# Polarfire SoC register map
Vendor: Microchip; File version: 1.0
CPU: Microchip PolarFire SoC 1.0, little endian
Registers are 32-bit, read-write, reset 0x0 unless marked. A register's access mark holds for its fields unless they carry their own. Offsets are from the block's base; [hi:lo] are bit positions; {n}, {i} and the like mark numbered series; 'fields as' and 'values as' point back to an identical list.

## CAN_A_LO — CAN_A_LO Controller
Base 0x2010C000
Same registers: CAN_B_LO 0x2010D000, CAN_A_HI 0x2810C000, CAN_B_HI 0x2810D000
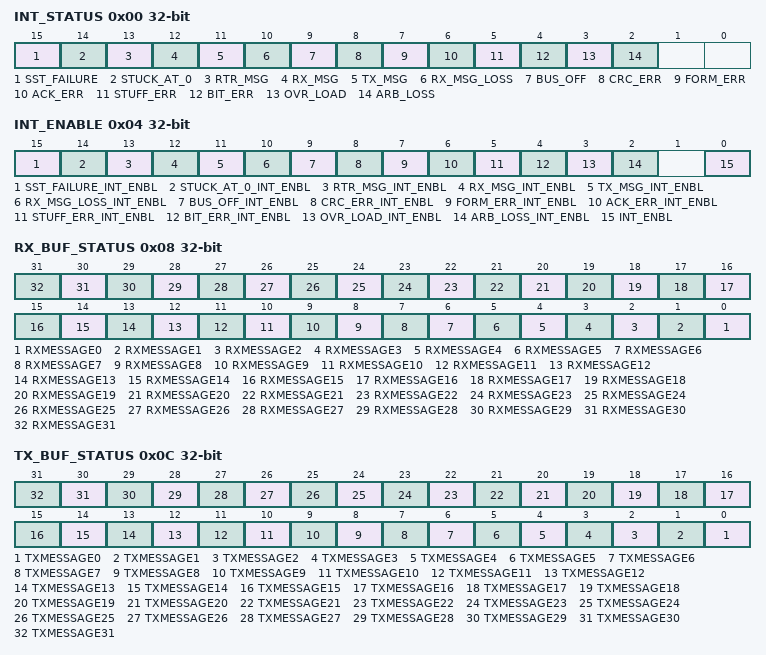
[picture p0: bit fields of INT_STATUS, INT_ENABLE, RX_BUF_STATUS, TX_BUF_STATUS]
0x00 INT_STATUS — Interrupt status register
  [15] SST_FAILURE — Single-shot transmission failure 0: Normal operation 1: A buffer set for single shot transmission experienced an arbitration loss or a bus error during transmission.
  [14] STUCK_AT_0 — Stuck at dominant error 0: Normal operation 1: Indicates if receive (RX) input remains stuck at 0 (dominant level) for more than 11 consecutive bit times.
  [13] RTR_MSG — RTR auto-reply message sent 0: Normal operation 1: Indicates that a RTR auto-reply message was sent.
  [12] RX_MSG — Receive message available 0: Normal operation 1: Indicates a new message was successfully received and stored in a receive buffer which has its RxIntEbl flag asserted.
  [11] TX_MSG — Message transmitted 0: Normal operation 1: Indicates a message was successfully sent from a transmit buffer which has its TxIntEbl flag asserted.
  [10] RX_MSG_LOSS — Received message lost 0: Normal operation 1: Indicates a newly received message couldn't be stored because the target message buffer was full (for example.. its MsgAv flag was set).
  [9] BUS_OFF — Bus Off 0: Normal operation 1: Indicates that the CAN controller entered the bus-off error state.
  [8] CRC_ERR — CRC error 0: Normal operation 1: Indicates that a CAN crc error is detected.
  [7] FORM_ERR — Format error 0: Normal operation 1: Indicates that a CAN format error is detected.
  [6] ACK_ERR — Acknowledge error 0: Normal operation 1: Indicates that a CAN message acknowledgement error is detected.
  [5] STUFF_ERR — Bit stuffing error 0: Normal operation 1: Indicates that a CAN bit stuffing error is detected.
  [4] BIT_ERR — Bit error 0: Normal operation 1: Indicates that a CAN bit error is detected.
  [3] OVR_LOAD — Overload message detected 0: Normal operation 1: Indicates that a CAN overload message is detected.
  [2] ARB_LOSS — Arbitration loss 0: Normal operation 1: The message arbitration was lost while sending a message. The message transmission is retried once the CAN bus is idle again.
0x04 INT_ENABLE — Interrupt enable register
  [15] SST_FAILURE_INT_ENBL — Single shot transmission failure interrupt enable.
  [14] STUCK_AT_0_INT_ENBL — Stuck at dominant error interrupt enable.
  [13] RTR_MSG_INT_ENBL — RTR auto-reply message sent interrupt enable.
  [12] RX_MSG_INT_ENBL — Receive message available interrupt enable.
  [11] TX_MSG_INT_ENBL — Message transmitted interrupt enable.
  [10] RX_MSG_LOSS_INT_ENBL — Received message lost interrupt enable.
  [9] BUS_OFF_INT_ENBL — Bus off interrupt enable.
  [8] CRC_ERR_INT_ENBL — CRC error interrupt enable.
  [7] FORM_ERR_INT_ENBL — Format error interrupt enable.
  [6] ACK_ERR_INT_ENBL — Acknowledge error interrupt enable.
  [5] STUFF_ERR_INT_ENBL — Bit stuffing error interrupt enable.
  [4] BIT_ERR_INT_ENBL — Bit error interrupt enable.
  [3] OVR_LOAD_INT_ENBL — Overload message detected interrupt enable.
  [2] ARB_LOSS_INT_ENBL — Arbitration loss interrupt enable.
  [0] INT_ENBL — Global interrupt enable flag. 0: All interrupts are disabled 1: Enabled interrupt sources are available
0x08 RX_BUF_STATUS ro — Receive (RX) message buffer status. This bundles message available (MsgAv) flags from all 32 receive message buffers.
  [n] RXMESSAGE{n} (n=0..31) — Message available in RxMessage buffer {n}
0x0C TX_BUF_STATUS ro — Transmit (TX) message buffer status.
  [n] TXMESSAGE{n} (n=0..31) — Message available in TxMessage buffer {n}
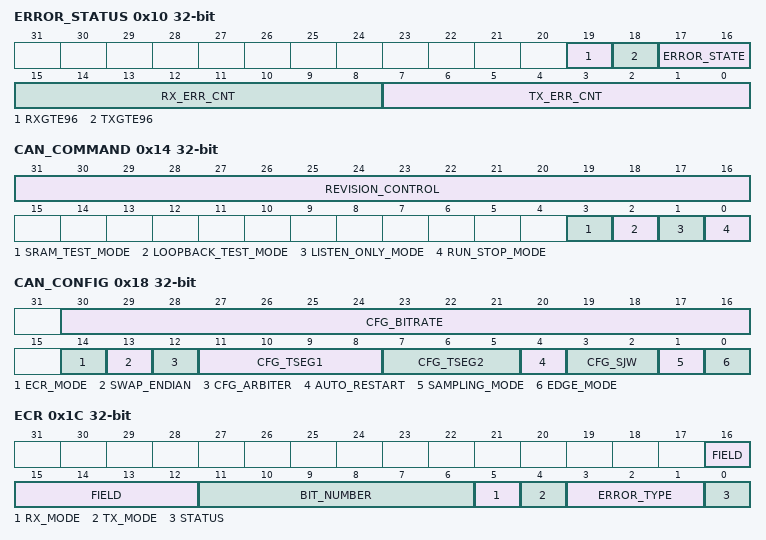
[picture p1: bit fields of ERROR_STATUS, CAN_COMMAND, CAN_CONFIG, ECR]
0x10 ERROR_STATUS ro — CAN error status indicator register
  [19] RXGTE96 — The receive error counter is greater or equal 96 dec.
  [18] TXGTE96 — The transmit error counter is greater or equal 96 dec.
  [17:16] ERROR_STATE — The error state of the CAN mode: 00: error active (normal operation) 01: error passive 1x: bus off
  [15:8] RX_ERR_CNT — The receive error counter as defined in CAN 2.0 specification. When in bus-off state.. this counter is used to count 128 groups of 11 receive bits.
  [7:0] TX_ERR_CNT — The transmit error counter as defined in CAN 2.0 specification. When it is greater than 255 dec.. it is fixed at 255 dec.
0x14 CAN_COMMAND — The CAN controller can be used in different operating modes. By disabling transmitting data.. it is possible to use the CAN in Listen-only mode.. enabling features such as automatic bit rate detection. Before starting the CAN controller.. all the CAN configuration registers have to be set according to the target application.
  [31:16] REVISION_CONTROL ro — This field contains the version of the CAN core in the following format. This is a read-only field. [major version].[minor version].[revision number] [31:28]: Major version [27:24]: Minor version [23:16]: Revision number
  [3] SRAM_TEST_MODE — SRAM Test mode 0: Normal operation 1: Enable SRAM Test mode.
  [2] LOOPBACK_TEST_MODE — Loopback-test mode 0: Normal operation 1: Loopback mode is enabled[1]: Listen-only mode.
  [1] LISTEN_ONLY_MODE — Listen-only mode 0: Active 1: CAN listen only. The output is held at 'R' level. The CAN controller is only listening.
  [0] RUN_STOP_MODE — Run/Stop mode 0: Sets the CAN controller into Stop mode. Returns 0 when stopped. 1: Sets the CAN controller into Run mode. Returns 1 when running.
0x18 CAN_CONFIG — CAN configuration register.
  [30:16] CFG_BITRATE — Configuration bit rate Prescaler for generating the time quantum which defines the TQ: 0: One time quantum equals 1 clock cycle 1: One time quantum equals 2 clock cycles 32767: One time quantum equals 32768 clock cycles
  [14] ECR_MODE — Error-capture mode 0: Free running. The ECR register shows the current bit position within the CAN frame. 1: Capture mode. The ECR register shows the bit position and type of the last captured CAN error.
  [13] SWAP_ENDIAN — The byte position of the CAN receive and transmit data fields can be modified to match the endian setting of the processor or the used CAN protocol. 0: CAN data byte position is not swapped (big endian). 1: CAN data byte position is swapped (little endian).
  [12] CFG_ARBITER — Transmit buffer arbiter 0: Round robin arbitration. 1: Fixed priority arbitration.
  [11:8] CFG_TSEG1 — Time segment 1. Time segment 1 includes the propagation time Length of the first time segment: tseg1 = CFG_TSEG1+1 CFG_TSEG1 = 0 and CFG_TSEG1 = 1 are not allowed.
  [7:5] CFG_TSEG2 — Time segment 2 Length of the second time segment: tseg2 = CFG_TSEG2+1 CFG_TSEG2 = 0 is not allowed. CFG_TSEG2 = 1 is only allowed in Direct-sampling mode.
  [4] AUTO_RESTART — The CAN can be set to restart either 'by hand' or automatically after a bus-off. 0: After bus-off.. the CAN must be restarted 'by hand'. This is the recommended setting. 1: After bus-off.. the CAN restarts automatically after 128 groups of 11 recessive bits.
  [3:2] CFG_SJW — Synchronization Jump Width 1 sjw is less than or equal to tseg1 and sjw is less than or equal to tseg2
  [1] SAMPLING_MODE — CAN bus bit sampling 0: One sampling point is used in the receiver path. 1: Three sampling points with majority decision are used.
  [0] EDGE_MODE — CAN bus synchronization logic 0: Edge from 'R' to 'D' is used for synchronization. 1: Both edges are used.
0x1C ECR — Error capture register
  [16:12] FIELD ro — This specifies the field of the ECR 0x00: Stopped 0x01: Synchronize 0x05: Interframe 0x06: Bus idle 0x07: Start of frame 0x08: Arbitration 0x09: Control 0x0A: Data 0x0B: CRC 0x0C: ACK 0x0D: End of frame 0x10: Error flag 0x11: Error echo 0x12: Error delimiter 0x18: Overload flag 0x19: Overload echo 0x1A: Overload delimiter Others: N/A
  [11:6] BIT_NUMBER ro — Bit number inside of field
  [5] RX_MODE ro — When asserted.. the CAN controller is the receiver.
  [4] TX_MODE — When asserted.. the CAN controller is the transmitter.
  [3:1] ERROR_TYPE — Specifies different error types 0: Arbitration loss 1: Bit error 2: Bit stuffing error 3: Acknowledge error 4: Form error 5: CRC error Others: N/A
  [0] STATUS — Status of the ECR register 0: The ECR register captured an error or is in free running mode. 1: The ECR register set to sample the event.
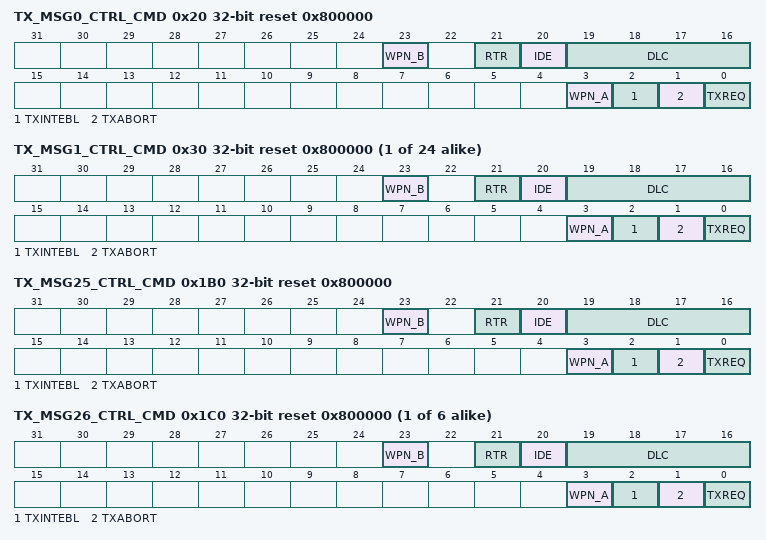
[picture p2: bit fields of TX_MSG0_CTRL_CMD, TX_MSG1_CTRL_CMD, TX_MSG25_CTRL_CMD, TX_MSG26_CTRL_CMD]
0x20 TX_MSG0_CTRL_CMD reset 0x800000 — Transmit Message0 buffer control and command register
  [23] WPN_B — Write protect not In case of control flag bit, 0: Bit[21:16] remain unchanged 1: The write protect is not set and bit[21:16] are modified.. by default. The read back value of this bit is undefined Note: Using the WPN flag enables simple retransmission of the same message by only having to set the TxReq and TxAbort flags without taking care of the special flags. In case of command flag bit, 0: Default and 1: prohibited
  [21] RTR — RTR; Remote bit. control flag bit 0: Standard message 1: RTR message
  [20] IDE — Extended identifier bit; Control flag bit 0: This is a standard format message 1: This is an extended format message
  [19:16] DLC — Data length code; Control flag bit Invalid values are transmitted as they are.. but the number of data bytes is limited to eight 0: Message has 0 data bytes 1: Message has 1 data byte ... 8: Message has 8 data bytes 9:15: Message has 8 data bytes
  [3] WPN_A — Write protect not. In case of control flag bit, 0: Bit[2] remains unchanged. 1: The write protect is not set and Bit[2] is modified.. default. In case of Command flag bit, 0:default, 1: prohibited
  [2] TXINTEBL — Tx interrupt enable; Control flag bit 0: Interrupt is disabled. 1: Interrupt enabled.. successful message transmission sets the TX_MSG flag in the interrupt controller.
  [1] TXABORT — Transmit abort request; Command flag bit 0: Idle 1: Requests removal of a pending message. The message is removed the next time an arbitration loss happens. The flag is cleared when the message is removed or when the message wins arbitration. The TxReq flag is cleared at the same time.
  [0] TXREQ — Transmit request; Command flag bit Write: 0: Idle. No message transmit request. 1: Message transmit request Note: The Tx message buffer must not be changed while TxReq is 1. Read: 0: TxReq completed 1: TxReq pending
{0x24+0x10*i} TX_MSG{i}_ID (i=0..24) — Transmit Message0 buffer identifier register
  [31:3] ID — Transmit message0 buffer identifier (29-bit wide)
{0x28+0x10*i} TX_MSG{i}_DATA_HIGH (i=0..31) — Transmit Message0 buffer data high register
  [31:0] TX_MSG{i}_DATA_HIGH — The byte mapping can be set using the CAN swap_endian configuration bit. swap_endian = 0.. default [31:24]: CAN data byte 1 [23:16]: CAN data byte 2 [15:8]: CAN data byte 3 [7:0]: CAN data byte 4 swap_endian = 1 [31:24]: CAN data byte 4 [23:16]: CAN data byte 3 [15:8]: CAN data byte 2 [7:0]: CAN data byte 1
{0x2C+0x10*i} TX_MSG{i}_DATA_LOW (i=0..31) — Transmit Message0 buffer data low register
  [31:0] TX_MSG{i}_DATA_LOW — The byte mapping can be set using the CAN swap_endian configuration bit swap_endian = 0.. default [31:24]: CAN data byte 5 [23:16]: CAN data byte 6 [15:8]: CAN data byte 7 [7:0]: CAN data byte 8 swap_endian = 1 [31:24]: CAN data byte 8 [23:16]: CAN data byte 7 [15:8]: CAN data byte 6 [7:0]: CAN data byte 5
{0x20+0x10*i} TX_MSG{i}_CTRL_CMD reset 0x800000 (i=1..24) — Transmit Message0 buffer control and command register
  [23] WPN_B — Write protect not 0: Bit[21:16] remain unchanged 1: The write protect is not set and bit[21:16] are modified.. by default. The read back value of this bit is undefined Note: Using the WPN flag enables simple retransmission of the same message by only having to set the TxReq and TxAbort flags without taking care of the special flags
  [21] RTR — RTR; control flag bit 0: Standard message 1: RTR message
  [20] IDE — Extended identifier bit; Control flag bit 0: This is a standard format message 1: This is an extended format message
  [19:16] DLC — Data length code; Control flag bit Invalid values are transmitted as they are.. but the number of data bytes is limited to eight 0: Message has 0 data bytes 1: Message has 1 data byte ... 8: Message has 8 data bytes 9:15: Message has 8 data bytes
  [3] WPN_A — Write protect not 0: Bit[2] remains unchanged. 1: The write protect is not set and Bit[2] is modified.. default.
  [2] TXINTEBL — Tx interrupt enable; Control flag bit 0: Interrupt is disabled. 1: Interrupt enabled.. successful message transmission sets the TX_MSG flag in the interrupt controller.
  [1] TXABORT — Transmit abort request; Command flag bit 0: Idle 1: Requests removal of a pending message. The message is removed the next time an arbitration loss happens. The flag is cleared when the message is removed or when the message wins arbitration. The TxReq flag is cleared at the same time.
  [0] TXREQ — Transmit request; Command flag bit Write: 0: Idle. No message transmit request. 1: Message transmit request Note: The Tx message buffer must not be changed while TxReq is 1. Read: 0: TxReq completed 1: TxReq pending
0x1B0 TX_MSG25_CTRL_CMD reset 0x800000 — Transmit Message0 buffer control and command register
  [23] WPN_B — Write protect not. In case of control flag bit, 0: Bit[21:16] remain unchanged 1: The write protect is not set and bit[21:16] are modified.. by default. The read back value of this bit is undefined Note: Using the WPN flag enables simple retransmission of the same message by only having to set the TxReq and TxAbort flags without taking care of the special flags. In case of command flag bit, 0: default and 1: prohibited
  [21] RTR — RTR; control flag bit 0: Standard message 1: RTR message
  [20] IDE — Extended identifier bit; Control flag bit 0: This is a standard format message 1: This is an extended format message
  [19:16] DLC — Data length code; Control flag bit Invalid values are transmitted as they are.. but the number of data bytes is limited to eight 0: Message has 0 data bytes 1: Message has 1 data byte ... 8: Message has 8 data bytes 9:15: Message has 8 data bytes
  [3] WPN_A — Write protect not. In case of control flag bit, 0: Bit[2] remains unchanged. 1: The write protect is not set and Bit[2] is modified.. default. In case of command flag bit 0:default and 1: prohibited
  [2] TXINTEBL — Tx interrupt enable; Control flag bit 0: Interrupt is disabled. 1: Interrupt enabled.. successful message transmission sets the TX_MSG flag in the interrupt controller.
  [1] TXABORT — Transmit abort request; Command flag bit 0: Idle 1: Requests removal of a pending message. The message is removed the next time an arbitration loss happens. The flag is cleared when the message is removed or when the message wins arbitration. The TxReq flag is cleared at the same time.
  [0] TXREQ — Transmit request; Command flag bit Write: 0: Idle. No message transmit request. 1: Message transmit request Note: The Tx message buffer must not be changed while TxReq is 1. Read: 0: TxReq completed 1: TxReq pending
0x1B4 TX_MSG25_ID — Transmit Message0 buffer identifier register
  [31:3] ID — Transmit message0 buffer: identifier (29-bit wide). [31:3]:ID[28:0]
{0x20+0x10*i} TX_MSG{i}_CTRL_CMD reset 0x800000 (i=26..31) — Transmit Message0 buffer control and command register
  fields as TX_MSG1_CTRL_CMD
{0x24+0x10*i} TX_MSG{i}_ID (i=26..31) — Transmit Message0 buffer identifier register
  [31:3] ID — Transmit message0 buffer identifier (29-bit wide)
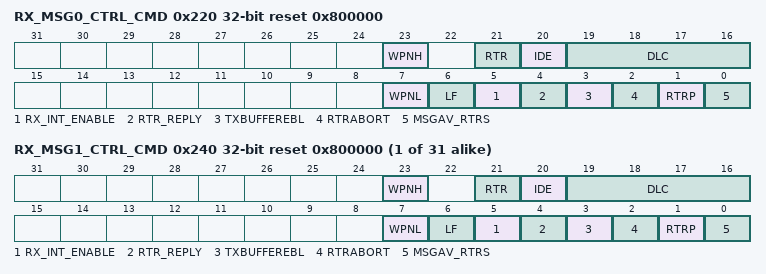
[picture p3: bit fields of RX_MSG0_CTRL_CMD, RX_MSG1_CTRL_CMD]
0x220 RX_MSG0_CTRL_CMD reset 0x800000 — Receive Message0 buffer command and control register
  [23] WPNH — Write protect not high. In case of control flag bit, 0: Bit[21:16] remain unchanged 1: The write protect is not set and bit[21:16] are modified.. default The read back value of this bit is undefined. In case of command flag bit, 0:default and 1: prohibited
  [21] RTR — RTR bit(Remote bit); Control bit 0: This is a regular message 1: This is an RTR message.
  [20] IDE — Extended identifier bit; Control bit 0: This is a standard format message. 1: This is an extended format message.
  [19:16] DLC — Data length code; Control bits 0: Message has 0 data byte. 1: Message has 1 data byte. ... 8: Message has 8 data bytes. 9:15: Message has 8 data bytes.
  [7] WPNL — Write protect not low. In case of control flag bit, 0: Bits[6:3] remain unchanged 1: This write protect is not set and bits[6:3] are modified.. default. This bit is always zero for read back. In case of command flag bit 0:default and 1: prohibited.
  [6] LF — Link flag; Control bit 0: This buffer is not linked to the next buffer 1: This buffer is linked with the next buffer
  [5] RX_INT_ENABLE — Receive interrupt enable; Control bit 0: Interrupt generation is disabled 1: Interrupt generation is enabled
  [4] RTR_REPLY — Automatic message reply upon receipt of an RTR message; Control bit 0: Automatic RTR message handling disabled 1: Automatic RTR message handling enabled
  [3] TXBUFFEREBL — Transaction buffer enable; Control bit 0: Buffer is disabled 1: Buffer is enabled
  [2] RTRABORT — RTR abort request; Command bit 0: Idle 1: Requests removal of a pending RTR message reply. The flag is cleared when the message was removed or when the message won arbitration. The TxReq flag is cleared at the same time
  [1] RTRP — RTReply pending; Command bit 0: No RTR reply request pending 1: RTR reply request pending
  [0] MSGAV_RTRS — Message available/RTR sent; Command bit If RTRreply flag is set.. this bit shows if an RTR auto-reply message has been sent.. otherwise it indicates if the buffer contains a valid message. Read 0: Idle 1: New message available (RTRreply = 0).. RTR auto-reply message sent (RTRreply = 1) Write 0: Idle 1: Acknowledges receipt of new message or transmission of RTR auto-reply message. Note: Before acknowledging receipt of a new message.. the message content must be copied into system memory. Acknowledging a message clears the MsgAv flag.
0x224 RX_MSG0_ID — Receive Message0 buffer Identifier register
  [31:3] ID — RxMessage0 buffer identifier (29-bit wide). [31:3]:ID[28:0]
{0x228+0x20*i} RX_MSG{i}_DATA_HIGH (i=0..26) — Receive Message{i} buffer data high register
  [31:0] RX_MSG{i}_DATA_HIGH — The byte mapping can be set using the CAN swap_endian configuration bit. swap_endian = 0.. default: [31:24]: CAN data byte 1 [23:16]: CAN data byte 2 [15:8]: CAN data byte 3 [7:0]: CAN data byte 4 swap_endian = 1 [31:24]: CAN data byte 4 [23:16]: CAN data byte 3 [15:8]: CAN data byte 2 [7:0]: CAN data byte 1
{0x22C+0x20*i} RX_MSG{i}_DATA_LOW (i=0..26) — Receive Message{i} buffer data low register
  [31:0] RX_MSG{i}_DATA_LOW — The byte mapping can be set using the CAN swap_endian configuration bit. swap_endian = 0.. default: [31:24]: CAN data byte 5 [23:16]: CAN data byte 6 [15:8]: CAN data byte 7 [7:0]: CAN data byte 8 swap_endian = 1 [31:24]: CAN data byte 8 [23:16]: CAN data byte 7 [15:8]: CAN data byte 6 [7:0]: CAN data byte 5
0x230 RX_MSG0_AMR — Acceptance mask register (AMR)
  [31:0] RX_MSG0_AMR — Receive Message0 buffer AMR bits.(Accepatnce Mask Register). [31:3]: Identifier [2]: IDE [1]: RTR [0]: Reserved AMR: 0: The incoming bit is checked against the respective ACR. The message is not accepted when the incoming bit does not match with the respective ACR flag. 1: The incoming bit is a "don't care".
0x234 RX_MSG0_ACR — Acceptance code register (ACR)
  [31:0] RX_MSG0_ACR — Receive Message0 buffer ACR bits. (Acceptance Code Register), [31:3]: Identifier [2]: IDE [1]: RTR [0]: N/A
0x238 RX_MSG0_AMR_DATA — AMR- Data
  [31:0] RX_MSG0_AMR_DATA — Receive Message0 buffer AMR Data bits.(Acceptance Mask Register-Data), [15:8]: CAN data byte 1 [7:0]: CAN data byte 2
0x23C RX_MSG0_ACR_DATA — ACR- Data
  [31:0] RX_MSG0_ACR_DATA — Receive Message0 buffer ACR Data bits. (Acceptance Code Register-Data): [15:8]: CAN data byte 1 [7:0]: CAN data byte 2
{0x220+0x20*i} RX_MSG{i}_CTRL_CMD reset 0x800000 (i=1..31) — Receive Message{i} buffer command and control register
  [23] WPNH — Write protect not high 0: Bit[21:16] remain unchanged 1: The write protect is not set and bit[21:16] are modified.. default The read back value of this bit is undefined
  [21] RTR — RTR bit; Control bit 0: This is a regular message 1: This is an RTR message.
  [20] IDE — Extended identifier bit; Control bit 0: This is a standard format message. 1: This is an extended format message.
  [19:16] DLC — Data length code; Control bits 0: Message has 0 data byte. 1: Message has 1 data byte. ... 8: Message has 8 data bytes. 9:15: Message has 8 data bytes.
  [7] WPNL — Write protect not low 0: Bits[6:3] remain unchanged 1: This write protect is not set and bits[6:3] are modified.. default. This bit is always zero for read back
  [6] LF — Link flag; Control bit 0: This buffer is not linked to the next buffer 1: This buffer is linked with the next buffer
  [5] RX_INT_ENABLE — Receive interrupt enable; Control bit 0: Interrupt generation is disabled 1: Interrupt generation is enabled
  [4] RTR_REPLY — Automatic message reply upon receipt of an RTR message; Control bit 0: Automatic RTR message handling disabled 1: Automatic RTR message handling enabled
  [3] TXBUFFEREBL — Transaction buffer enable; Control bit 0: Buffer is disabled 1: Buffer is enabled
  [2] RTRABORT — RTR abort request; Command bit 0: Idle 1: Requests removal of a pending RTR message reply. The flag is cleared when the message was removed or when the message won arbitration. The TxReq flag is cleared at the same time
  [1] RTRP — RTReply pending; Command bit 0: No RTR reply request pending 1: RTR reply request pending
  [0] MSGAV_RTRS — Message available/RTR sent; Command bit If RTRreply flag is set.. this bit shows if an RTR auto-reply message has been sent.. otherwise it indicates if the buffer contains a valid message. Read 0: Idle 1: New message available (RTRreply = 0).. RTR auto-reply message sent (RTRreply = 1) Write 0: Idle 1: Acknowledges receipt of new message or transmission of RTR auto-reply message. Note: Before acknowledging receipt of a new message.. the message content must be copied into system memory. Acknowledging a message clears the MsgAv flag.
{0x224+0x20*i} RX_MSG{i}_ID (i=1..31) — Receive Message{i} buffer Identifier register
  [31:3] ID — RxMessage0 buffer identifier (29-bit wide)
{0x230+0x20*i} RX_MSG{i}_AMR (i=1..31) — Acceptance mask register (AMR)
  [31:0] RX_MSG{i}_AMR — Receive Message{i} buffer AMR bits [31:3]: Identifier [2]: IDE [1]: RTR [0]: Reserved AMR: 0: The incoming bit is checked against the respective ACR. The message is not accepted when the incoming bit does not match with the respective ACR flag. 1: The incoming bit is a "don't care"
{0x234+0x20*i} RX_MSG{i}_ACR (i=1..31) — Acceptance code register (ACR)
  [31:0] RX_MSG{i}_ACR — Receive Message{i} buffer ACR bits [31:3]: Identifier [2]: IDE [1]: RTR [0]: N/A
{0x238+0x20*i} RX_MSG{i}_AMR_DATA (i=1..31) — AMR- Data
  [31:0] RX_MSG{i}_AMR_DATA — Receive Message{i} buffer AMR Data bits [15:8]: CAN data byte 1 [7:0]: CAN data byte 2
{0x23C+0x20*i} RX_MSG{i}_ACR_DATA (i=1..31) — ACR- Data
  [31:0] RX_MSG{i}_ACR_DATA — Receive Message{i} buffer ACR Data bits [15:8]: CAN data byte 1 [7:0]: CAN data byte 2
0x588 RX_MSG27_DATA_LOW — Receive Message27 buffer data low register
  [31:0] RX_MSG27_DATA_LOW — The byte mapping can be set using the CAN swap_endian configuration bit. swap_endian = 0.. default: [31:24]: CAN data byte 5 [23:16]: CAN data byte 6 [15:8]: CAN data byte 7 [7:0]: CAN data byte 8 swap_endian = 1 [31:24]: CAN data byte 8 [23:16]: CAN data byte 7 [15:8]: CAN data byte 6 [7:0]: CAN data byte 5
0x58C RX_MSG27_DATA_HIGH — Receive Message27 buffer data high register
  [31:0] RX_MSG27_DATA_HIGH — The byte mapping can be set using the CAN swap_endian configuration bit. swap_endian = 0.. default: [31:24]: CAN data byte 1 [23:16]: CAN data byte 2 [15:8]: CAN data byte 3 [7:0]: CAN data byte 4 swap_endian = 1 [31:24]: CAN data byte 4 [23:16]: CAN data byte 3 [15:8]: CAN data byte 2 [7:0]: CAN data byte 1
{0x228+0x20*i} RX_MSG{i}_DATA_HIGH (i=28..31) — Receive Message{i} buffer data high register
  fields as RX_MSG0_DATA_HIGH
{0x22C+0x20*i} RX_MSG{i}_DATA_LOW (i=28..31) — Receive Message{i} buffer data low register
  fields as RX_MSG0_DATA_LOW
